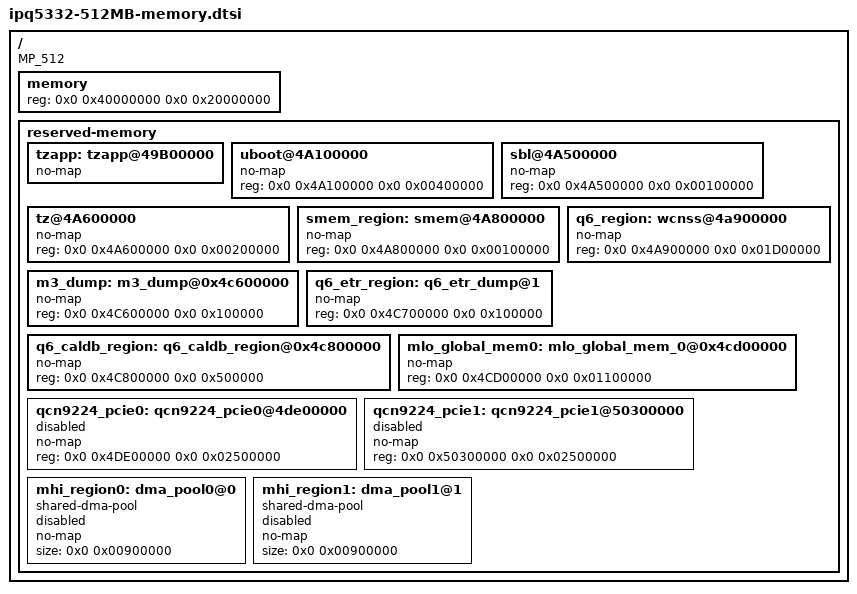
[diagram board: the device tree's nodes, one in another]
// SPDX-License-Identifier: (GPL-2.0+ OR BSD-3-Clause)
/*
 * Dev SoC Memory device tree source
 *
 * Copyright (c) 2022 Qualcomm Innovation Center, Inc. All rights reserved.
 */

/ {
	MP_512;

	/*		  512MB Profile
	 * +=========+==============+========================+
	 * |        |              |                         |
	 * | Region | Start Offset |          Size           |
	 * |        |              |                         |
	 * +--------+--------------+-------------------------+
	 * |        |              |                         |
	 * |        |              |                         |
	 * |        |              |                         |
	 * |        |              |                         |
	 * | Linux  |  0x40000000  |          161MB          |
	 * |        |              |                         |
	 * |        |              |                         |
	 * |        |              |                         |
	 * +--------+--------------+-------------------------+
	 * |        |              |                         |
	 * | uboot  |  0x4A100000  |           4MB           |
	 * |        |              |                         |
	 * +--------+--------------+-------------------------+
	 * |  SBL   |  0x4A500000  |           1MB           |
	 * +--------+--------------+-------------------------+
	 * |        |              |                         |
	 * |  TZ    |  0x4A600000  |           2MB           |
	 * |        |              |                         |
	 * +--------+--------------+-------------------------+
	 * |  smem  |  0x4A800000  |           1MB           |
	 * +--------+--------------+-------------------------+
	 * |        |              |                         |
	 * |        |              |                         |
	 * | WLAN   |              |                         |
	 * |   Q6   |  0x4A900000  |          29MB           |
	 * |        |              |                         |
	 * |        |              |                         |
	 * +--------+--------------+-------------------------+
         * | M3 Dump|  0x4C600000  |          1MB            |
         * +--------+--------------+-------------------------+
	 * | WLAN   |              |                         |
	 * | Q6 ETR |  0x4C700000  |          1MB            |
	 * | Region |              |                         |
	 * +--------+--------------+-------------------------+
	 * | caldb  |  0x4C800000  |           5MB           |
	 * +--------+--------------+-------------------------+
	 * |  MLO   |  0x4CD00000  |          17MB           |
	 * +--------+--------------+-------------------------+
	 * |        |              |                         |
	 * |  WKK0  |  0x4DE00000  |          37MB           |
	 * |        |              |                         |
	 * +--------+--------------+-------------------------+
	 * |        |              |                         |
	 * |  WKK1  |  0x50300000  |          37MB           |
	 * |        |              |                         |
	 * +--------+--------------+-------------------------+
	 * |        |              |                         |
	 * |  MHI0  |    DYNAMIC   |          9MB            |
	 * |        |              |                         |
	 * +--------+--------------+-------------------------+
	 * |        |              |                         |
	 * |  MHI1  |    DYNAMIC   |          9MB            |
	 * +=================================================+
	 * |                                                 |
	 * |                                                 |
	 * |                                                 |
	 * |            Rest of memory for Linux             |
	 * |                                                 |
	 * |                                                 |
	 * |                                                 |
	 * +=================================================+
	 */

	memory {
		device_type = "memory";
		reg = <0x0 0x40000000 0x0 0x20000000>;
	};

	reserved-memory {
		#address-cells = <2>;
		#size-cells = <2>;
		ranges;

		tzapp: tzapp@49B00000 {
			no-map;
		};

		uboot@4A100000 {
			no-map;
			reg = <0x0 0x4A100000 0x0 0x00400000>;
		};

		sbl@4A500000 {
			no-map;
			reg = <0x0 0x4A500000 0x0 0x00100000>;
		};

		tz@4A600000 {
			no-map;
			reg = <0x0 0x4A600000 0x0 0x00200000>;
		};

		smem_region: smem@4A800000 {
			no-map;
			reg = <0x0 0x4A800000 0x0 0x00100000>;
		};

		q6_region: wcnss@4a900000 {
			no-map;
			reg = <0x0 0x4A900000 0x0 0x01D00000>;
		};

		m3_dump: m3_dump@0x4c600000 {
			no-map;
			reg = <0x0 0x4C600000 0x0 0x100000>;
		};

		q6_etr_region: q6_etr_dump@1 {
			no-map;
			reg = <0x0 0x4C700000 0x0 0x100000>;
		};

		q6_caldb_region:q6_caldb_region@0x4c800000 {
                        no-map;
                        reg = <0x0 0x4C800000 0x0 0x500000>;
                };

		mlo_global_mem0: mlo_global_mem_0@0x4cd00000 {
			no-map;
			reg = <0x0 0x4CD00000 0x0 0x01100000>;
		};

		qcn9224_pcie0: qcn9224_pcie0@4de00000 {
			no-map;
			reg = <0x0 0x4DE00000 0x0 0x02500000>;
			status = "disabled";
		};

		qcn9224_pcie1: qcn9224_pcie1@50300000 {
			no-map;
			reg = <0x0 0x50300000 0x0 0x02500000>;
			status = "disabled";
		};

		mhi_region0: dma_pool0@0 {
			compatible = "shared-dma-pool";
			no-map;
			size = <0x0 0x00900000>;
			status = "disabled";
		};

		mhi_region1: dma_pool1@1 {
			compatible = "shared-dma-pool";
			no-map;
			size = <0x0 0x00900000>;
			status = "disabled";
		};
	};
};
